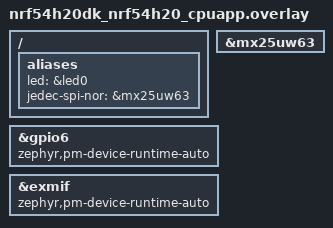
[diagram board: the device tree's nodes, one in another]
&mx25uw63 {
	status = "okay";
};

&gpio6 {
	status = "okay";
	zephyr,pm-device-runtime-auto;
};

&exmif {
	status = "okay";
	zephyr,pm-device-runtime-auto;
};

/ {
	aliases {
		led = &led0;
		/delete-property/ led1;
		jedec-spi-nor = &mx25uw63;
	};
};

/delete-node/ &led1;
